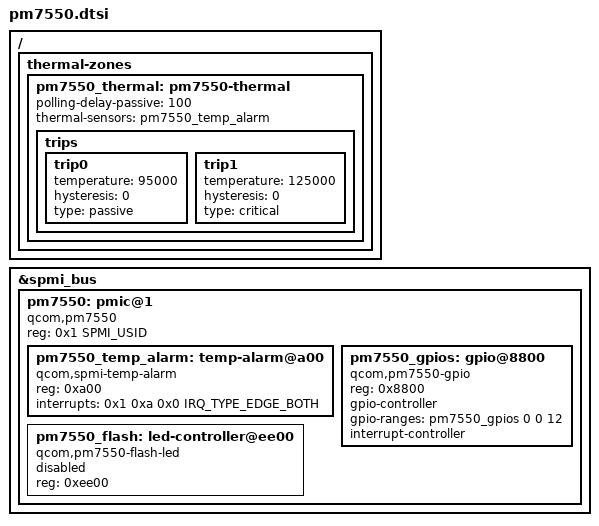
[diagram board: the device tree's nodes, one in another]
// SPDX-License-Identifier: BSD-3-Clause
/*
 * Copyright (c) 2025, Luca Weiss <luca.weiss@fairphone.com>
 */

#include <dt-bindings/interrupt-controller/irq.h>
#include <dt-bindings/spmi/spmi.h>

/ {
	thermal-zones {
		pm7550_thermal: pm7550-thermal {
			polling-delay-passive = <100>;

			thermal-sensors = <&pm7550_temp_alarm>;

			trips {
				trip0 {
					temperature = <95000>;
					hysteresis = <0>;
					type = "passive";
				};

				trip1 {
					/*
					 * Current Linux driver currently only supports up to
					 * 125°C, should be updated to 145°C once available.
					 */
					temperature = <125000>;
					hysteresis = <0>;
					type = "critical";
				};
			};
		};
	};
};

&spmi_bus {
	pm7550: pmic@1 {
		compatible = "qcom,pm7550", "qcom,spmi-pmic";
		reg = <0x1 SPMI_USID>;
		#address-cells = <1>;
		#size-cells = <0>;

		pm7550_temp_alarm: temp-alarm@a00 {
			compatible = "qcom,spmi-temp-alarm";
			reg = <0xa00>;
			interrupts = <0x1 0xa 0x0 IRQ_TYPE_EDGE_BOTH>;
			#thermal-sensor-cells = <0>;
		};

		pm7550_gpios: gpio@8800 {
			compatible = "qcom,pm7550-gpio", "qcom,spmi-gpio";
			reg = <0x8800>;
			gpio-controller;
			gpio-ranges = <&pm7550_gpios 0 0 12>;
			#gpio-cells = <2>;
			interrupt-controller;
			#interrupt-cells = <2>;
		};

		pm7550_flash: led-controller@ee00 {
			compatible = "qcom,pm7550-flash-led", "qcom,spmi-flash-led";
			reg = <0xee00>;
			status = "disabled";
		};
	};
};
